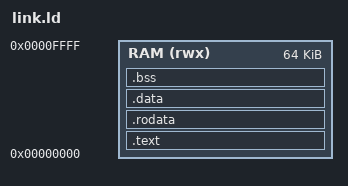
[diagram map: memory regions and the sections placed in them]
ENTRY(_start)

MEMORY {
    RAM (rwx) : ORIGIN = 0x00000000, LENGTH = 64K
}

SECTIONS {
    /* Make sure that any data is pressed in the RAM section */
    .text : { *(.text.start) *(.text*) } > RAM
    .rodata : { *(.rodata*) } > RAM
    .data : { *(.data*) } > RAM
    .bss : { *(.bss*) } > RAM

    . = ALIGN(16);
    _stack_top = ORIGIN(RAM) + LENGTH(RAM);
}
